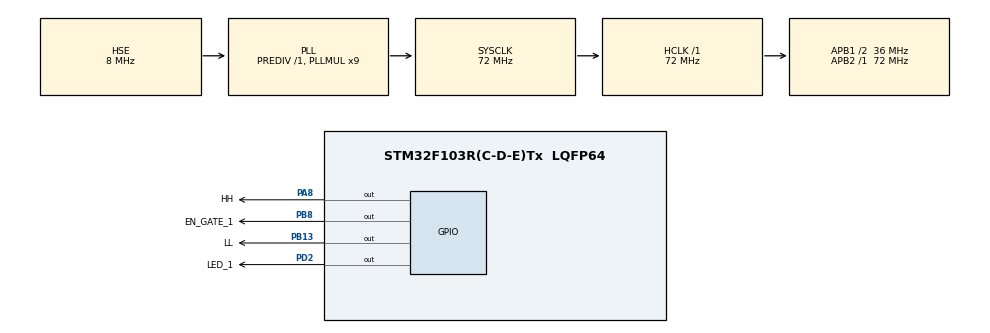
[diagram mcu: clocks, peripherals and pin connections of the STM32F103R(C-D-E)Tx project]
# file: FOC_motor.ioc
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Mcu.Family=STM32F1
Mcu.Name=STM32F103R(C-D-E)Tx
Mcu.Package=LQFP64
NVIC.PriorityGroup=NVIC_PRIORITYGROUP_4
NVIC.TIM2_IRQn=true\:0\:0\:false\:false\:true\:true\:true\:true
NVIC.TIM3_IRQn=true\:0\:0\:false\:false\:true\:true\:true\:true
PA13.Mode=Serial_Wire
PA13.Signal=SYS_JTMS-SWDIO
PA14.Mode=Serial_Wire
PA14.Signal=SYS_JTCK-SWCLK
PA8.GPIO_Label=HH
PA8.PinState=GPIO_PIN_SET
PA8.Signal=GPIO_Output
PB13.GPIO_Label=LL
PB13.Signal=GPIO_Output
PB8.GPIO_Label=EN_GATE_1
PB8.PinState=GPIO_PIN_SET
PB8.Signal=GPIO_Output
PD0-OSC_IN.Mode=HSE-External-Oscillator
PD0-OSC_IN.Signal=RCC_OSC_IN
PD1-OSC_OUT.Mode=HSE-External-Oscillator
PD1-OSC_OUT.Signal=RCC_OSC_OUT
PD2.GPIO_Label=LED_1
PD2.Signal=GPIO_Output
ProjectManager.HeapSize=0x200
ProjectManager.StackSize=0x400
ProjectManager.TargetToolchain=Makefile
RCC.AHBFreq_Value=72000000
RCC.APB1CLKDivider=RCC_HCLK_DIV2
RCC.APB1Freq_Value=36000000
RCC.APB1TimFreq_Value=72000000
RCC.APB2Freq_Value=72000000
RCC.APB2TimFreq_Value=72000000
RCC.HCLKFreq_Value=72000000
RCC.PLLMUL=RCC_PLL_MUL9
RCC.PLLSourceVirtual=RCC_PLLSOURCE_HSE
RCC.SYSCLKFreq_VALUE=72000000
RCC.SYSCLKSource=RCC_SYSCLKSOURCE_PLLCLK
RCC.USBFreq_Value=72000000
TIM1.AutoReloadPreload=TIM_AUTORELOAD_PRELOAD_ENABLE
TIM1.Period=10000
TIM1.Prescaler=71
TIM2.AutoReloadPreload=TIM_AUTORELOAD_PRELOAD_ENABLE
TIM2.Channel-Output\ Compare1\ No\ Output=TIM_CHANNEL_1
TIM2.OC1Preload=DISABLE
TIM2.OCMode_1=TIM_OCMODE_TOGGLE
TIM2.Period=100
TIM2.Prescaler=72-1
TIM2.Pulse-Output\ Compare1\ No\ Output=50
TIM2.TIM_MasterOutputTrigger=TIM_TRGO_RESET
TIM3.Channel-Output\ Compare1\ No\ Output=TIM_CHANNEL_1
TIM3.Channel-Output\ Compare2\ No\ Output=TIM_CHANNEL_2
TIM3.Channel-Output\ Compare3\ No\ Output=TIM_CHANNEL_3
TIM3.Prescaler=72-1
TIM8.Period=10000
TIM8.Prescaler=71
VP_TIM1_VS_ClockSourceINT.Mode=Internal
VP_TIM2_VS_ClockSourceINT.Mode=Internal
VP_TIM2_VS_no_output1.Mode=Output Compare1 No Output
VP_TIM3_VS_ClockSourceINT.Mode=Internal
VP_TIM3_VS_no_output1.Mode=Output Compare1 No Output
VP_TIM3_VS_no_output2.Mode=Output Compare2 No Output
VP_TIM3_VS_no_output3.Mode=Output Compare3 No Output
VP_TIM8_VS_ClockSourceINT.Mode=Internal
board=custom

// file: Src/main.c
/* USER CODE BEGIN Header */
/**
  ******************************************************************************
  * @file           : main.c
  * @brief          : Main program body
  ******************************************************************************
  * @attention
  *
  * <h2><center>&copy; Copyright (c) 2024 STMicroelectronics.
  * All rights reserved.</center></h2>
  *
  * This software component is licensed by ST under BSD 3-Clause license,
  * the "License"; You may not use this file except in compliance with the
  * License. You may obtain a copy of the License at:
  *                        opensource.org/licenses/BSD-3-Clause
  *
  ******************************************************************************
  */
/* USER CODE END Header */
#include "main.h"
#include "stm32f1xx_hal.h"
#include "tim.h"
#include "gpio.h"

/* USER CODE BEGIN Includes */
// #include "as5600.h"
// #include "stdint.h"
// #include "stm32f103xb.h"
// #include "stm32f101x6.h"
/* USER CODE END Includes */

/* USER CODE BEGIN PV */
int count = 0;
int compare;
/* USER CODE END PV */

void SystemClock_Config(void);

int main(void)
{

  /* MCU Configuration--------------------------------------------------------*/

  /* Reset of all peripherals, Initializes the Flash interface and the Systick. */
  HAL_Init();

  /* Configure the system clock */
  SystemClock_Config();

  /* Initialize all configured peripherals */
  MX_GPIO_Init();
  MX_TIM2_Init();
  MX_TIM3_Init();
  MX_TIM1_Init();
  MX_TIM8_Init();
  /* USER CODE BEGIN 2 */
  // HAL_TIM_PWM_Start(&htim1, TIM_CHANNEL_1|TIM_CHANNEL_2|TIM_CHANNEL_3);
  // HAL_TIMEx_PWMN_Start(&htim1, TIM_CHANNEL_1|TIM_CHANNEL_2|TIM_CHANNEL_3);
  /* USER CODE END 2 */

  /* Infinite loop */
  /* USER CODE BEGIN WHILE */
  while (1)
  {
    // for (unsigned int i=0; i<10000; i++){
    //   __HAL_TIM_SET_COMPARE(&htim1, TIM_CHANNEL_1, i);
    //   __HAL_TIM_SET_COMPARE(&htim1, TIM_CHANNEL_2, i);
    //   __HAL_TIM_SET_COMPARE(&htim1, TIM_CHANNEL_3, i);
    //   HAL_Delay(1);
    // }
    // for (unsigned int i=10000; i>0; i--){
    //   __HAL_TIM_SET_COMPARE(&htim1, TIM_CHANNEL_1, i);
    //   __HAL_TIM_SET_COMPARE(&htim1, TIM_CHANNEL_2, i);
    //   __HAL_TIM_SET_COMPARE(&htim1, TIM_CHANNEL_3, i);
    //   HAL_Delay(1);
    // }

    HAL_Delay(1000);
    /* USER CODE END WHILE */

  }
}

void SystemClock_Config(void)
{
  RCC_OscInitTypeDef RCC_OscInitStruct = {0};
  RCC_ClkInitTypeDef RCC_ClkInitStruct = {0};

  /** Initializes the RCC Oscillators according to the specified parameters
  * in the RCC_OscInitTypeDef structure.
  */
  RCC_OscInitStruct.OscillatorType = RCC_OSCILLATORTYPE_HSE;
  RCC_OscInitStruct.HSEState = RCC_HSE_ON;
  RCC_OscInitStruct.HSEPredivValue = RCC_HSE_PREDIV_DIV1;
  RCC_OscInitStruct.HSIState = RCC_HSI_ON;
  RCC_OscInitStruct.PLL.PLLState = RCC_PLL_ON;
  RCC_OscInitStruct.PLL.PLLSource = RCC_PLLSOURCE_HSE;
  RCC_OscInitStruct.PLL.PLLMUL = RCC_PLL_MUL9;
  if (HAL_RCC_OscConfig(&RCC_OscInitStruct) != HAL_OK)
  {
    Error_Handler();
  }

  /** Initializes the CPU, AHB and APB buses clocks
  */
  RCC_ClkInitStruct.ClockType = RCC_CLOCKTYPE_HCLK|RCC_CLOCKTYPE_SYSCLK
                              |RCC_CLOCKTYPE_PCLK1|RCC_CLOCKTYPE_PCLK2;
  RCC_ClkInitStruct.SYSCLKSource = RCC_SYSCLKSOURCE_PLLCLK;
  RCC_ClkInitStruct.AHBCLKDivider = RCC_SYSCLK_DIV1;
  RCC_ClkInitStruct.APB1CLKDivider = RCC_HCLK_DIV2;
  RCC_ClkInitStruct.APB2CLKDivider = RCC_HCLK_DIV1;

  if (HAL_RCC_ClockConfig(&RCC_ClkInitStruct, FLASH_LATENCY_2) != HAL_OK)
  {
    Error_Handler();
  }
}

void Error_Handler(void)
{
  __disable_irq();
  while (1)
  {
  }
}
